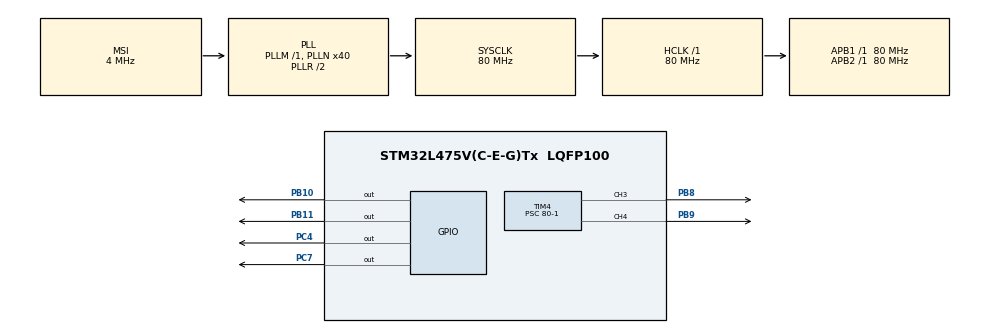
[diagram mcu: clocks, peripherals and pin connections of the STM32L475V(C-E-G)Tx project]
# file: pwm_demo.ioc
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Mcu.Family=STM32L4
Mcu.Name=STM32L475V(C-E-G)Tx
Mcu.Package=LQFP100
NVIC.PriorityGroup=NVIC_PRIORITYGROUP_4
PA13\ (JTMS-SWDIO).Mode=Serial_Wire
PA13\ (JTMS-SWDIO).Signal=SYS_JTMS-SWDIO
PA14\ (JTCK-SWCLK).Mode=Serial_Wire
PA14\ (JTCK-SWCLK).Signal=SYS_JTCK-SWCLK
PB10.Signal=GPIO_Output
PB11.Signal=GPIO_Output
PB8.Signal=S_TIM4_CH3
PB9.Signal=S_TIM4_CH4
PC4.Signal=GPIO_Output
PC7.Signal=GPIO_Output
PH0-OSC_IN\ (PH0).Mode=HSE-External-Oscillator
PH0-OSC_IN\ (PH0).Signal=RCC_OSC_IN
PH1-OSC_OUT\ (PH1).Mode=HSE-External-Oscillator
PH1-OSC_OUT\ (PH1).Signal=RCC_OSC_OUT
ProjectManager.HeapSize=0x200
ProjectManager.StackSize=0x400
ProjectManager.TargetToolchain=MDK-ARM V5
RCC.ADCFreq_Value=16000000
RCC.AHBFreq_Value=80000000
RCC.APB1Freq_Value=80000000
RCC.APB1TimFreq_Value=80000000
RCC.APB2Freq_Value=80000000
RCC.APB2TimFreq_Value=80000000
RCC.CortexFreq_Value=80000000
RCC.HCLKFreq_Value=80000000
RCC.HSE_VALUE=8000000
RCC.HSI_VALUE=16000000
RCC.LSE_VALUE=32768
RCC.MSI_VALUE=4000000
RCC.PLLN=40
RCC.SYSCLKFreq_VALUE=80000000
RCC.SYSCLKSource=RCC_SYSCLKSOURCE_PLLCLK
RCC.USBFreq_Value=16000000
RCC.VCOOutputFreq_Value=160000000
SH.S_TIM4_CH3.0=TIM4_CH3,PWM Generation3 CH3
SH.S_TIM4_CH4.0=TIM4_CH4,PWM Generation4 CH4
TIM4.Channel-PWM\ Generation3\ CH3=TIM_CHANNEL_3
TIM4.Channel-PWM\ Generation4\ CH4=TIM_CHANNEL_4
TIM4.Period=50-1
TIM4.Prescaler=80-1
board=custom

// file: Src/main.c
/* USER CODE BEGIN Header */
/**
  ******************************************************************************
  * @file           : main.c
  * @brief          : Main program body
  ******************************************************************************
  * @attention
  *
  * <h2><center>&copy; Copyright (c) 2019 STMicroelectronics.
  * All rights reserved.</center></h2>
  *
  * This software component is licensed by ST under BSD 3-Clause license,
  * the "License"; You may not use this file except in compliance with the
  * License. You may obtain a copy of the License at:
  *                        opensource.org/licenses/BSD-3-Clause
  *
  ******************************************************************************
  */
/* USER CODE END Header */

#include "main.h"

/* USER CODE BEGIN Includes */
#include "motors.h"
/* USER CODE END Includes */

TIM_HandleTypeDef htim4;

/* USER CODE BEGIN PV */
MOTOR_STATUS status = MOTORS_STOP;
/* USER CODE END PV */

void SystemClock_Config(void);
static void MX_GPIO_Init(void);
static void MX_TIM4_Init(void);

int main(void)
{

  /* MCU Configuration--------------------------------------------------------*/

  /* Reset of all peripherals, Initializes the Flash interface and the Systick. */
  HAL_Init();

  /* Configure the system clock */
  SystemClock_Config();

  /* Initialize all configured peripherals */
  MX_GPIO_Init();
  MX_TIM4_Init();
  /* USER CODE BEGIN 2 */
  Motors_Init();
  /* USER CODE END 2 */

  /* Infinite loop */
  /* USER CODE BEGIN WHILE */
  while (1)
  {
    update_motors(&status);
    /* USER CODE END WHILE */

  }
}

void SystemClock_Config(void)
{
  RCC_OscInitTypeDef RCC_OscInitStruct = {0};
  RCC_ClkInitTypeDef RCC_ClkInitStruct = {0};

  /** Initializes the CPU, AHB and APB busses clocks
  */
  RCC_OscInitStruct.OscillatorType = RCC_OSCILLATORTYPE_MSI;
  RCC_OscInitStruct.MSIState = RCC_MSI_ON;
  RCC_OscInitStruct.MSICalibrationValue = 0;
  RCC_OscInitStruct.MSIClockRange = RCC_MSIRANGE_6;
  RCC_OscInitStruct.PLL.PLLState = RCC_PLL_ON;
  RCC_OscInitStruct.PLL.PLLSource = RCC_PLLSOURCE_MSI;
  RCC_OscInitStruct.PLL.PLLM = 1;
  RCC_OscInitStruct.PLL.PLLN = 40;
  RCC_OscInitStruct.PLL.PLLP = RCC_PLLP_DIV7;
  RCC_OscInitStruct.PLL.PLLQ = RCC_PLLQ_DIV2;
  RCC_OscInitStruct.PLL.PLLR = RCC_PLLR_DIV2;
  if (HAL_RCC_OscConfig(&RCC_OscInitStruct) != HAL_OK)
  {
    Error_Handler();
  }
  /** Initializes the CPU, AHB and APB busses clocks
  */
  RCC_ClkInitStruct.ClockType = RCC_CLOCKTYPE_HCLK|RCC_CLOCKTYPE_SYSCLK
                              |RCC_CLOCKTYPE_PCLK1|RCC_CLOCKTYPE_PCLK2;
  RCC_ClkInitStruct.SYSCLKSource = RCC_SYSCLKSOURCE_PLLCLK;
  RCC_ClkInitStruct.AHBCLKDivider = RCC_SYSCLK_DIV1;
  RCC_ClkInitStruct.APB1CLKDivider = RCC_HCLK_DIV1;
  RCC_ClkInitStruct.APB2CLKDivider = RCC_HCLK_DIV1;

  if (HAL_RCC_ClockConfig(&RCC_ClkInitStruct, FLASH_LATENCY_4) != HAL_OK)
  {
    Error_Handler();
  }
  /** Configure the main internal regulator output voltage
  */
  if (HAL_PWREx_ControlVoltageScaling(PWR_REGULATOR_VOLTAGE_SCALE1) != HAL_OK)
  {
    Error_Handler();
  }
}

static void MX_TIM4_Init(void)
{

  TIM_MasterConfigTypeDef sMasterConfig = {0};
  TIM_OC_InitTypeDef sConfigOC = {0};

  htim4.Instance = TIM4;
  htim4.Init.Prescaler = 80-1;
  htim4.Init.CounterMode = TIM_COUNTERMODE_UP;
  htim4.Init.Period = 50-1;
  htim4.Init.ClockDivision = TIM_CLOCKDIVISION_DIV1;
  htim4.Init.AutoReloadPreload = TIM_AUTORELOAD_PRELOAD_DISABLE;
  if (HAL_TIM_PWM_Init(&htim4) != HAL_OK)
  {
    Error_Handler();
  }
  sMasterConfig.MasterOutputTrigger = TIM_TRGO_RESET;
  sMasterConfig.MasterSlaveMode = TIM_MASTERSLAVEMODE_DISABLE;
  if (HAL_TIMEx_MasterConfigSynchronization(&htim4, &sMasterConfig) != HAL_OK)
  {
    Error_Handler();
  }
  sConfigOC.OCMode = TIM_OCMODE_PWM1;
  sConfigOC.Pulse = 0;
  sConfigOC.OCPolarity = TIM_OCPOLARITY_HIGH;
  sConfigOC.OCFastMode = TIM_OCFAST_DISABLE;
  if (HAL_TIM_PWM_ConfigChannel(&htim4, &sConfigOC, TIM_CHANNEL_3) != HAL_OK)
  {
    Error_Handler();
  }
  if (HAL_TIM_PWM_ConfigChannel(&htim4, &sConfigOC, TIM_CHANNEL_4) != HAL_OK)
  {
    Error_Handler();
  }
  HAL_TIM_MspPostInit(&htim4);

}

static void MX_GPIO_Init(void)
{
  GPIO_InitTypeDef GPIO_InitStruct = {0};

  /* GPIO Ports Clock Enable */
  __HAL_RCC_GPIOH_CLK_ENABLE();
  __HAL_RCC_GPIOC_CLK_ENABLE();
  __HAL_RCC_GPIOB_CLK_ENABLE();
  __HAL_RCC_GPIOA_CLK_ENABLE();

  /*Configure GPIO pin Output Level */
  HAL_GPIO_WritePin(GPIOC, GPIO_PIN_4|GPIO_PIN_7, GPIO_PIN_RESET);

  /*Configure GPIO pin Output Level */
  HAL_GPIO_WritePin(GPIOB, GPIO_PIN_10|GPIO_PIN_11, GPIO_PIN_RESET);

  /*Configure GPIO pins : PC4 PC7 */
  GPIO_InitStruct.Pin = GPIO_PIN_4|GPIO_PIN_7;
  GPIO_InitStruct.Mode = GPIO_MODE_OUTPUT_PP;
  GPIO_InitStruct.Pull = GPIO_NOPULL;
  GPIO_InitStruct.Speed = GPIO_SPEED_FREQ_LOW;
  HAL_GPIO_Init(GPIOC, &GPIO_InitStruct);

  /*Configure GPIO pins : PB10 PB11 */
  GPIO_InitStruct.Pin = GPIO_PIN_10|GPIO_PIN_11;
  GPIO_InitStruct.Mode = GPIO_MODE_OUTPUT_PP;
  GPIO_InitStruct.Pull = GPIO_NOPULL;
  GPIO_InitStruct.Speed = GPIO_SPEED_FREQ_LOW;
  HAL_GPIO_Init(GPIOB, &GPIO_InitStruct);

}

void Error_Handler(void)
{
}

/************************ (C) COPYRIGHT STMicroelectronics *****END OF FILE****/
